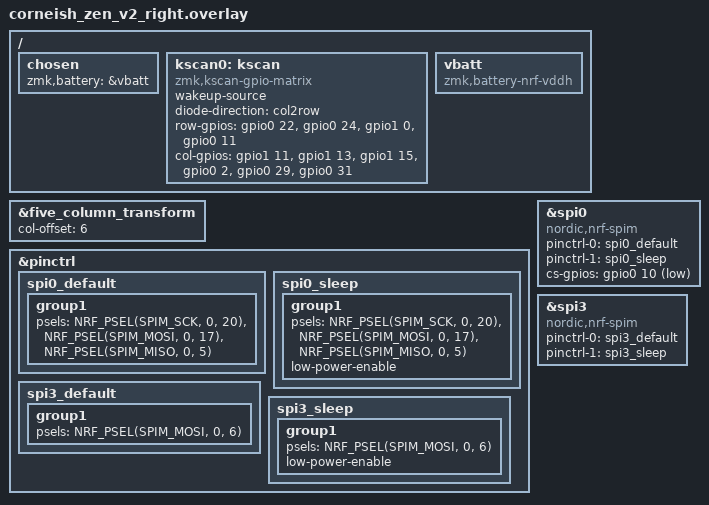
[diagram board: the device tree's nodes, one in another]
/*
*
* Copyright (c) 2021 Darryl deHaan
* SPDX-License-Identifier: MIT
*
*/
#include "corneish_zen_v2.dtsi"


/{
    chosen {
        zmk,battery = &vbatt;
    };

    kscan0: kscan {
        compatible = "zmk,kscan-gpio-matrix";
        wakeup-source;
        diode-direction = "col2row";
        row-gpios
            = <&gpio0 22 (GPIO_ACTIVE_HIGH | GPIO_PULL_DOWN)>
            , <&gpio0 24 (GPIO_ACTIVE_HIGH | GPIO_PULL_DOWN)>
            , <&gpio1 0 (GPIO_ACTIVE_HIGH | GPIO_PULL_DOWN)>
            , <&gpio0 11 (GPIO_ACTIVE_HIGH | GPIO_PULL_DOWN)>
            ;

        col-gpios
            = <&gpio1 11 GPIO_ACTIVE_HIGH>
            , <&gpio1 13 GPIO_ACTIVE_HIGH>
            , <&gpio1 15 GPIO_ACTIVE_HIGH>
            , <&gpio0 2 GPIO_ACTIVE_HIGH>
            , <&gpio0  29 GPIO_ACTIVE_HIGH>
            , <&gpio0  31 GPIO_ACTIVE_HIGH>
            ;
    };

     vbatt: vbatt {
        compatible = "zmk,battery-nrf-vddh";
    };

};

&five_column_transform {
    col-offset = <6>;
};

&pinctrl {
    spi0_default: spi0_default {
        group1 {
            psels = <NRF_PSEL(SPIM_SCK, 0, 20)>,
                <NRF_PSEL(SPIM_MOSI, 0, 17)>,
                <NRF_PSEL(SPIM_MISO, 0, 5)>;
        };
    };

    spi0_sleep: spi0_sleep {
        group1 {
            psels = <NRF_PSEL(SPIM_SCK, 0, 20)>,
                <NRF_PSEL(SPIM_MOSI, 0, 17)>,
                <NRF_PSEL(SPIM_MISO, 0, 5)>;
            low-power-enable;
        };
    };
    spi3_default: spi3_default {
        group1 {
            psels = <NRF_PSEL(SPIM_MOSI, 0, 6)>; // WS2812_VEXT_DATA
        };
    };

    spi3_sleep: spi3_sleep {
        group1 {
            psels = <NRF_PSEL(SPIM_MOSI, 0, 6)>;
            low-power-enable;
        };
    };
};

&spi0 {
    status = "okay";
    compatible = "nordic,nrf-spim";
    pinctrl-0 = <&spi0_default>;
    pinctrl-1 = <&spi0_sleep>;
    pinctrl-names = "default", "sleep";
    cs-gpios = <&gpio0 10 GPIO_ACTIVE_LOW>;
};

&spi3 {
    compatible = "nordic,nrf-spim";
    status = "okay";

    pinctrl-0 = <&spi3_default>;
    pinctrl-1 = <&spi3_sleep>;
    pinctrl-names = "default", "sleep";
};
